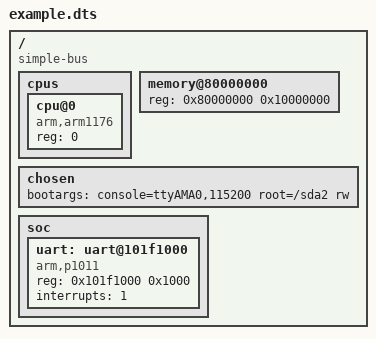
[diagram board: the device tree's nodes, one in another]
 /dts-v1/;

/ {

    #address-cells = <1>;
    #size-cells = <1>;
    compatible = "simple-bus";
    ranges;

    cpus {
        #address-cells = <1>;
        #size-cells = <0>;

        cpu@0 {
            device_type = "cpu";
            compatible = "arm,arm1176";
            reg = <0>;
        };
    };


    memory@80000000 {
        device_type = "memory";
        reg = <0x80000000 0x10000000>;  /* Start at 0x80000000, 64 MB size */
    };

    chosen {
    bootargs = "console=ttyAMA0,115200 root=/sda2 rw";
    };

    soc{
    #address-cells = <1>;
        #size-cells = <1>;
        uart: uart@101f1000{
        compatible = "arm,p1011";
        reg = <0x101f1000 0x1000>;
        interrupts = <1>;
        };
        };

};


	
